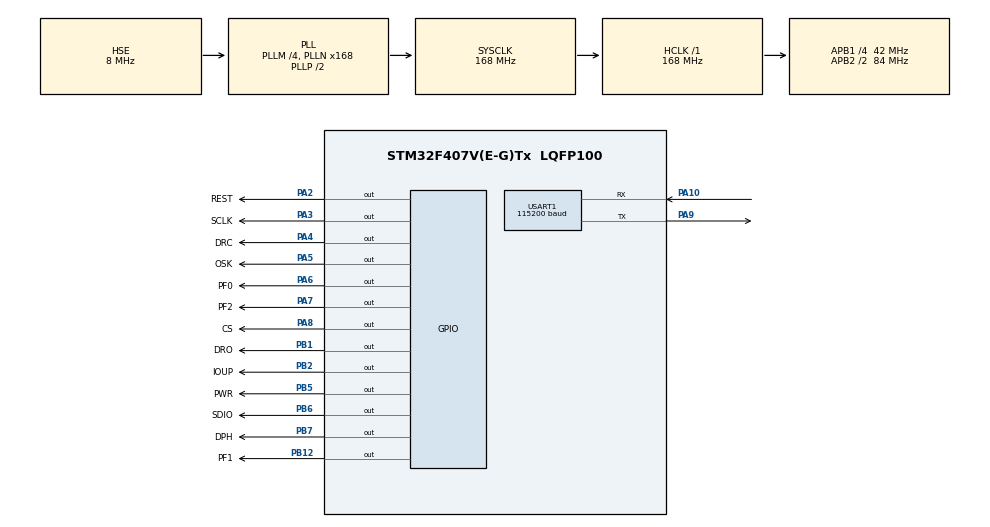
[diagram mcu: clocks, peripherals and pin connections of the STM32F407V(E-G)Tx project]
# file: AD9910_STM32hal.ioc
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Mcu.Family=STM32F4
Mcu.Name=STM32F407V(E-G)Tx
Mcu.Package=LQFP100
NVIC.PriorityGroup=NVIC_PRIORITYGROUP_4
PA10.Mode=Asynchronous
PA10.Signal=USART1_RX
PA13.Mode=Serial_Wire
PA13.Signal=SYS_JTMS-SWDIO
PA14.Mode=Serial_Wire
PA14.Signal=SYS_JTCK-SWCLK
PA2.GPIO_Label=REST
PA2.GPIO_Speed=GPIO_SPEED_FREQ_VERY_HIGH
PA2.PinState=GPIO_PIN_SET
PA2.Signal=GPIO_Output
PA3.GPIO_Label=SCLK
PA3.GPIO_Speed=GPIO_SPEED_FREQ_VERY_HIGH
PA3.PinState=GPIO_PIN_SET
PA3.Signal=GPIO_Output
PA4.GPIO_Label=DRC
PA4.GPIO_Speed=GPIO_SPEED_FREQ_VERY_HIGH
PA4.PinState=GPIO_PIN_SET
PA4.Signal=GPIO_Output
PA5.GPIO_Label=OSK
PA5.GPIO_Speed=GPIO_SPEED_FREQ_VERY_HIGH
PA5.PinState=GPIO_PIN_SET
PA5.Signal=GPIO_Output
PA6.GPIO_Label=PF0
PA6.GPIO_Speed=GPIO_SPEED_FREQ_VERY_HIGH
PA6.PinState=GPIO_PIN_SET
PA6.Signal=GPIO_Output
PA7.GPIO_Label=PF2
PA7.GPIO_Speed=GPIO_SPEED_FREQ_VERY_HIGH
PA7.PinState=GPIO_PIN_SET
PA7.Signal=GPIO_Output
PA8.GPIO_Label=CS
PA8.GPIO_Speed=GPIO_SPEED_FREQ_VERY_HIGH
PA8.PinState=GPIO_PIN_SET
PA8.Signal=GPIO_Output
PA9.Mode=Asynchronous
PA9.Signal=USART1_TX
PB1.GPIO_Label=DRO
PB1.GPIO_Speed=GPIO_SPEED_FREQ_VERY_HIGH
PB1.PinState=GPIO_PIN_SET
PB1.Signal=GPIO_Output
PB12.GPIO_Label=PF1
PB12.GPIO_Speed=GPIO_SPEED_FREQ_VERY_HIGH
PB12.PinState=GPIO_PIN_SET
PB12.Signal=GPIO_Output
PB2.GPIO_Label=IOUP
PB2.GPIO_Speed=GPIO_SPEED_FREQ_VERY_HIGH
PB2.PinState=GPIO_PIN_SET
PB2.Signal=GPIO_Output
PB5.GPIO_Label=PWR
PB5.GPIO_ModeDefaultOutputPP=GPIO_MODE_OUTPUT_PP
PB5.GPIO_Speed=GPIO_SPEED_FREQ_VERY_HIGH
PB5.PinState=GPIO_PIN_SET
PB5.Signal=GPIO_Output
PB6.GPIO_Label=SDIO
PB6.GPIO_Speed=GPIO_SPEED_FREQ_VERY_HIGH
PB6.PinState=GPIO_PIN_SET
PB6.Signal=GPIO_Output
PB7.GPIO_Label=DPH
PB7.GPIO_Speed=GPIO_SPEED_FREQ_VERY_HIGH
PB7.PinState=GPIO_PIN_SET
PB7.Signal=GPIO_Output
PH0-OSC_IN.Mode=HSE-External-Oscillator
PH0-OSC_IN.Signal=RCC_OSC_IN
PH1-OSC_OUT.Mode=HSE-External-Oscillator
PH1-OSC_OUT.Signal=RCC_OSC_OUT
ProjectManager.HeapSize=0x200
ProjectManager.StackSize=0x400
ProjectManager.TargetToolchain=CMake
RCC.48MHZClocksFreq_Value=84000000
RCC.AHBFreq_Value=168000000
RCC.APB1CLKDivider=RCC_HCLK_DIV4
RCC.APB1Freq_Value=42000000
RCC.APB1TimFreq_Value=84000000
RCC.APB2CLKDivider=RCC_HCLK_DIV2
RCC.APB2Freq_Value=84000000
RCC.APB2TimFreq_Value=168000000
RCC.CortexFreq_Value=168000000
RCC.FLatency=FLASH_LATENCY_5
RCC.HCLKFreq_Value=168000000
RCC.HSE_VALUE=8000000
RCC.HSI_VALUE=16000000
RCC.PLLM=4
RCC.PLLN=168
RCC.PLLSourceVirtual=RCC_PLLSOURCE_HSE
RCC.SYSCLKFreq_VALUE=168000000
RCC.SYSCLKSource=RCC_SYSCLKSOURCE_PLLCLK
RCC.VCOOutputFreq_Value=336000000
USART1.BaudRate=115200
USART1.Mode=MODE_TX_RX
USART1.OverSampling=UART_OVERSAMPLING_16
USART1.Parity=PARITY_NONE
USART1.StopBits=STOPBITS_1
USART1.VirtualMode=VM_ASYNC
USART1.WordLength=WORDLENGTH_8B
board=custom

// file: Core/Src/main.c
/* USER CODE BEGIN Header */
/**
  ******************************************************************************
  * @file           : main.c
  * @brief          : Main program body
  ******************************************************************************
  * @attention
  *
  * Copyright (c) 2024 STMicroelectronics.
  * All rights reserved.
  *
  * This software is licensed under terms that can be found in the LICENSE file
  * in the root directory of this software component.
  * If no LICENSE file comes with this software, it is provided AS-IS.
  *
  ******************************************************************************
  */
/* USER CODE END Header */
#include "main.h"
#include "usart.h"
#include "gpio.h"

/* USER CODE BEGIN Includes */
#include "stdio.h"
#include "AD9910.h"
/* USER CODE END Includes */

/* USER CODE BEGIN PV */
extern uchar cfr2[4]; //cfr2控制字
extern uchar cfr1[4]; //cfr1控制字
/* USER CODE END PV */

void SystemClock_Config(void);

int main(void)
{

  /* MCU Configuration--------------------------------------------------------*/

  /* Reset of all peripherals, Initializes the Flash interface and the Systick. */
  HAL_Init();

  /* Configure the system clock */
  SystemClock_Config();

  /* Initialize all configured peripherals */
  MX_GPIO_Init();
  MX_USART1_UART_Init();
  /* USER CODE BEGIN 2 */

	HAL_Delay(72);	//初始化延时函数
	Init_ad9910();

/*
//设置数字斜坡频率扫频，并使能自动双向扫频
	AD9910_DRG_FreInit_AutoSet(ENABLE);		//ENABLE,自动扫频，无需外加控制；DISABLE,手动扫频，由DRCTL引脚控制扫频
//设置（下限频率，上限频率，上扫频频率步进，下扫频频率步进，上扫频频点维持时间，下扫频频点维持时间）
	AD9910_DRG_FrePara_Set(100000, 100000000, 100, 100, 100,100);						//慢速扫频，方便观察， 约800mS,扫频时间计算参考函数注解
	//AD9910_DRG_FrePara_Set(400000, 300000000, 1200000, 2200000, 100,300);	//高速扫频，400K~300M,约263uS,扫频时间计算参考函数注解
																																					//上扫频每点维持100个控制字时间，下扫频每点维持300个控制字时间，
																																					//实际可以将该参数设置到更小，可以获得极高的扫描速度
*/

/*
//RAM模式,任意波形输出*/
// AD9910_RAM_WAVE_Set(TRIG_WAVE);	//设置模块输出三角波TRIG_WAVE：三角波，SQUARE_WAVE：方波，SINC_WAVE：SINC波

/*
//单频调制模式*/
  Freq_convert(1000);   //设置频率为1k,正弦波
  Write_Amplitude(500); //设置幅值（1-800mV）幅度设置为粗略设置

  /* USER CODE END 2 */

  /* Infinite loop */
  while (1)
  {

  }
}

void SystemClock_Config(void)
{
  RCC_OscInitTypeDef RCC_OscInitStruct = {0};
  RCC_ClkInitTypeDef RCC_ClkInitStruct = {0};

  /** Configure the main internal regulator output voltage
  */
  __HAL_RCC_PWR_CLK_ENABLE();
  __HAL_PWR_VOLTAGESCALING_CONFIG(PWR_REGULATOR_VOLTAGE_SCALE1);

  /** Initializes the RCC Oscillators according to the specified parameters
  * in the RCC_OscInitTypeDef structure.
  */
  RCC_OscInitStruct.OscillatorType = RCC_OSCILLATORTYPE_HSE;
  RCC_OscInitStruct.HSEState = RCC_HSE_ON;
  RCC_OscInitStruct.PLL.PLLState = RCC_PLL_ON;
  RCC_OscInitStruct.PLL.PLLSource = RCC_PLLSOURCE_HSE;
  RCC_OscInitStruct.PLL.PLLM = 4;
  RCC_OscInitStruct.PLL.PLLN = 168;
  RCC_OscInitStruct.PLL.PLLP = RCC_PLLP_DIV2;
  RCC_OscInitStruct.PLL.PLLQ = 4;
  if (HAL_RCC_OscConfig(&RCC_OscInitStruct) != HAL_OK)
  {
    Error_Handler();
  }

  /** Initializes the CPU, AHB and APB buses clocks
  */
  RCC_ClkInitStruct.ClockType = RCC_CLOCKTYPE_HCLK|RCC_CLOCKTYPE_SYSCLK
                              |RCC_CLOCKTYPE_PCLK1|RCC_CLOCKTYPE_PCLK2;
  RCC_ClkInitStruct.SYSCLKSource = RCC_SYSCLKSOURCE_PLLCLK;
  RCC_ClkInitStruct.AHBCLKDivider = RCC_SYSCLK_DIV1;
  RCC_ClkInitStruct.APB1CLKDivider = RCC_HCLK_DIV4;
  RCC_ClkInitStruct.APB2CLKDivider = RCC_HCLK_DIV2;

  if (HAL_RCC_ClockConfig(&RCC_ClkInitStruct, FLASH_LATENCY_5) != HAL_OK)
  {
    Error_Handler();
  }
}

void Error_Handler(void)
{
  __disable_irq();
  while (1)
  {
  }
}
